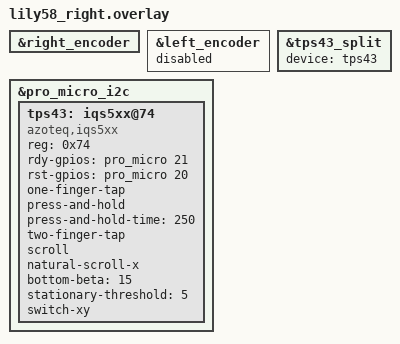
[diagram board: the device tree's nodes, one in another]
#include "lily58.dtsi"

&right_encoder { status = "okay"; };
&left_encoder { status = "disabled"; };

&pro_micro_i2c {
    status = "okay";
    tps43: iqs5xx@74 {
        status = "okay";
        compatible = "azoteq,iqs5xx";
        reg = <0x74>;

        rdy-gpios = <&pro_micro 21 GPIO_ACTIVE_HIGH>;  /* Ready pin */
        rst-gpios = <&pro_micro 20 GPIO_ACTIVE_HIGH>;  /* Reset pin */

        one-finger-tap;
        press-and-hold;
        press-and-hold-time = <250>;
        two-finger-tap;

        scroll;
        natural-scroll-x;

        bottom-beta = <15>;
        stationary-threshold = <5>;

        switch-xy;
    };
};

&tps43_split {
    device = <&tps43>;
};
